VERSION ""

NS_ :

BS_:

BU_: Gateway Dashboard DMS BCM
VAL_TABLE_ vtbSensorReqCause 15 "SNA" 2 "by Request 2" 1 "by Request 1" 0 "normal cycle" ;
VAL_TABLE_ vtbErrorDescription 255 "ERROR" ;

BO_ 2 ECM_broken_s: 1 Gateway
 SG_ sig_broken : 0|1@1+ (1,0) [0|1] "flag"  Dashboard

BO_ 1 ECM_broken_m: 1 Gateway
 SG_ sig_broken : 0|1@1+ (1,0) [0|1] "flag"  Dashboard

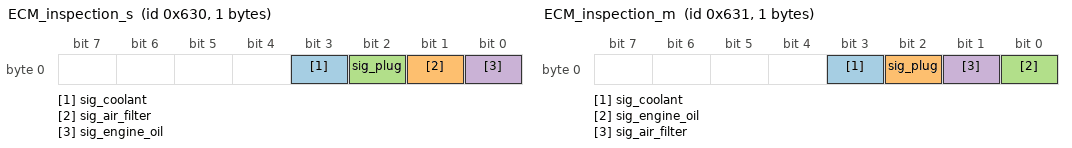
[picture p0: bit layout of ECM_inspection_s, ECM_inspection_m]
BO_ 1584 ECM_inspection_s: 1 Gateway
 SG_ sig_coolant : 3|1@1+ (1,0) [0|1] "flag"  Dashboard
 SG_ sig_air_filter : 1|1@1+ (1,0) [0|1] "flag"  Dashboard
 SG_ sig_plug : 2|1@1+ (1,0) [0|1] "flag"  Dashboard
 SG_ sig_engine_oil : 0|1@1+ (1,0) [0|1] "flag"  Dashboard

BO_ 1585 ECM_inspection_m: 1 Gateway
 SG_ sig_coolant : 3|1@1+ (1,0) [0|1] "flag"  Dashboard
 SG_ sig_plug : 2|1@1+ (1,0) [0|1] "flag"  Dashboard
 SG_ sig_engine_oil : 0|1@1+ (1,0) [0|1] "flag"  Dashboard
 SG_ sig_air_filter : 1|1@1+ (1,0) [0|1] "flag"  Dashboard

BO_ 305 DMS_driverstate: 2 DMS
 SG_ sig_injured : 8|7@1+ (1,0) [0|100] "%" Vector__XXX
 SG_ sig_droswy : 0|7@1+ (1,0) [0|127] "%"  Dashboard,BCM

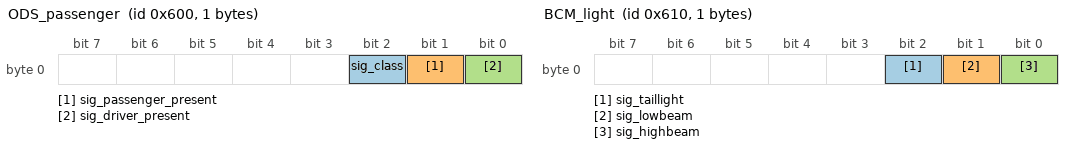
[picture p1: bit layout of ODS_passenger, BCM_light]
BO_ 1536 ODS_passenger: 1 Gateway
 SG_ sig_class : 2|1@1+ (1,0) [0|1] "flag"  Dashboard,BCM
 SG_ sig_passenger_present : 1|1@1+ (1,0) [0|1] "flag"  BCM,Dashboard
 SG_ sig_driver_present : 0|1@1+ (1,0) [0|1] "flag"  Dashboard,BCM

BO_ 256 ACU_crashstate: 1 Gateway
 SG_ sig_crashstate : 0|1@1+ (1,0) [0|1] ""  Dashboard,BCM

BO_ 528 BCM_seatbelt: 1 BCM
 SG_ sig_passenger_belt : 1|1@1+ (1,0) [0|1] "flag"  Gateway
 SG_ sig_driver_belt : 0|1@1+ (1,0) [0|1] "flag"  Gateway

BO_ 306 BCM_hazard: 1 BCM
 SG_ sig_hazard : 0|1@1+ (1,0) [0|1] "flag"  Gateway

BO_ 1552 BCM_light: 1 BCM
 SG_ sig_taillight : 2|1@1+ (1,0) [0|1] ""  Gateway
 SG_ sig_lowbeam : 1|1@1+ (1,0) [0|1] "flag"  Gateway
 SG_ sig_highbeam : 0|1@1+ (1,0) [0|1] "flag"  Gateway

BA_DEF_  "Manufacturer" STRING ;
BA_DEF_ BU_  "NodeLayerModules" STRING ;
BA_DEF_  "BusType" STRING ;
BA_DEF_ SG_  "GenSigSendType" ENUM  "Cyclic","OnWrite","OnWriteWithRepetition","OnChange","OnChangeWithRepetition","IfActive","IfActiveWithRepetition","NoSigSendType","NotUsed","NotUsed","NotUsed","NotUsed","NotUsed";
BA_DEF_ BO_  "GenMsgSendType" ENUM  "Cyclic","NotUsed","NotUsed","NotUsed","NotUsed","Cyclic","NotUsed","IfActive","NoMsgSendType","NotUsed","vector_leerstring";
BA_DEF_ BO_  "GenMsgCycleTime" INT 0 50000;
BA_DEF_ BO_  "GenMsgCycleTimeFast" INT 0 50000;
BA_DEF_ BO_  "GenMsgILSupport" ENUM  "No","Yes";
BA_DEF_DEF_  "Manufacturer" "Vector";
BA_DEF_DEF_  "NodeLayerModules" "CANoeILNLVector.dll";
BA_DEF_DEF_  "BusType" "CAN";
BA_DEF_DEF_  "GenSigSendType" "Cyclic";
BA_DEF_DEF_  "GenMsgSendType" "NoMsgSendType";
BA_DEF_DEF_  "GenMsgCycleTime" 200;
BA_DEF_DEF_  "GenMsgCycleTimeFast" 20;
BA_DEF_DEF_  "GenMsgILSupport" "Yes";
BA_ "GenMsgCycleTime" BO_ 2 0;
BA_ "GenMsgCycleTime" BO_ 1 0;
BA_ "GenMsgCycleTime" BO_ 305 5;
BA_ "GenMsgSendType" BO_ 305 0;
BA_ "GenMsgCycleTime" BO_ 256 5;
BA_ "GenMsgSendType" BO_ 256 0;
BA_ "GenMsgCycleTime" BO_ 528 0;
BA_ "GenMsgCycleTime" BO_ 306 5;
BA_ "GenMsgSendType" BO_ 306 0;
BA_ "GenSigSendType" SG_ 2 sig_broken 7;
BA_ "GenSigSendType" SG_ 1 sig_broken 7;
BA_ "GenSigSendType" SG_ 1584 sig_coolant 7;
BA_ "GenSigSendType" SG_ 1584 sig_air_filter 7;
BA_ "GenSigSendType" SG_ 1584 sig_plug 7;
BA_ "GenSigSendType" SG_ 1584 sig_engine_oil 7;
BA_ "GenSigSendType" SG_ 1585 sig_coolant 7;
BA_ "GenSigSendType" SG_ 1585 sig_plug 7;
BA_ "GenSigSendType" SG_ 1585 sig_engine_oil 7;
BA_ "GenSigSendType" SG_ 1585 sig_air_filter 7;
BA_ "GenSigSendType" SG_ 1536 sig_class 7;
BA_ "GenSigSendType" SG_ 1536 sig_passenger_present 7;
BA_ "GenSigSendType" SG_ 1536 sig_driver_present 7;
BA_ "GenSigSendType" SG_ 528 sig_passenger_belt 7;
BA_ "GenSigSendType" SG_ 528 sig_driver_belt 7;
BA_ "GenSigSendType" SG_ 1552 sig_taillight 7;
BA_ "GenSigSendType" SG_ 1552 sig_lowbeam 7;
BA_ "GenSigSendType" SG_ 1552 sig_highbeam 7;
